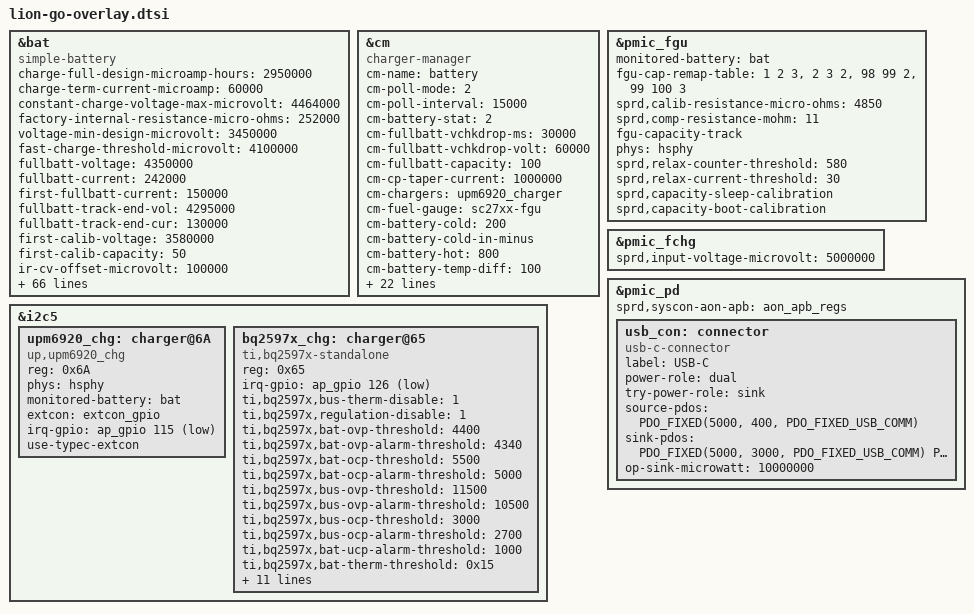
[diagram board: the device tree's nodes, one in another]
// SPDX-License-Identifier: GPL-2.0-only
/*
 * Unisoc Qogirl6 platform DTS file
 *
 * Copyright (C) 2020, Unisoc Inc.
 */

#include <dt-bindings/usb/pd.h>

&bat {
	compatible = "simple-battery";
	status = "okay";
	charge-full-design-microamp-hours = <2950000>;
	charge-term-current-microamp = <60000>;
	constant-charge-voltage-max-microvolt = <4464000>;
	factory-internal-resistance-micro-ohms = <252000>;
	voltage-min-design-microvolt = <3450000>;

	fast-charge-threshold-microvolt = <4100000>;
	fullbatt-voltage = <4350000>;
	fullbatt-current = <242000>;
	first-fullbatt-current = <150000>;
	fullbatt-track-end-vol = <4295000>;
	fullbatt-track-end-cur = <130000>;
	first-calib-voltage = <3580000>;
	first-calib-capacity = <50>;

	ir-cv-offset-microvolt = <100000>;
	ir-rc-micro-ohms = <20000>;
	ir-us-upper-limit-microvolt = <4500000>;

	ocv-capacity-celsius = <20>;
	ocv-capacity-table-0 = <4313000 100>, <4254000 95>, <4201000 90>,
				<4151000 85>, <4102000 80>, <4060000 75>,
				<4006000 70>, <3973000 65>, <3930000 60>,
				<3882000 55>, <3851000 50>, <3829000 45>,
				<3810000 40>, <3795000 35>, <3781000 30>,
				<3765000 25>, <3746000 20>, <3722000 15>,
				<3694000 10>, <3682000 5>, <3400000 0>;
	voltage-temp-table = <1110270 800>, <999440 850>, <890430 900>,
				<785590 950>, <687630 1000>, <598220 1050>,
				<517680 1100>, <446100 1150>, <383390 1200>,
				<328950 1250>, <281840 1300>, <241480 1350>,
				<207030 1400>, <177580 1450>, <152490 1500>,
				<131160 1550>, <113000 1600>, <97790 1650>;
	capacity-temp-table = <45 100>, <25 100>, <10 100>, <0 95>, <(-10) 90>;
	resistance-temp-table = <45 53>, <25 100>, <10 395>, <0 567>, <(-10) 793>;
	charge-sdp-current-microamp = <500000 500000>;
	charge-dcp-current-microamp = <3200000 3200000>;
	charge-cdp-current-microamp = <1500000 1500000>;
	charge-unknown-current-microamp = <1000000 1000000>;
	charge-fchg-current-microamp = <3000000 2000000>;
	charge-flash-current-microamp = <5000000 2700000>;

	cap-calib-energy-density-ocv-table = <3350000 3800000>, <4150000 4350000>;
	cap-track-energy-density-ocv-table = <3400000 3722000>;

	dcp-jeita-temp-table = <800 830 0 4200000>,<1000 1003 1000000 4200000>, <1100 1103 3200000 4500000>,
		<1150 1153 3200000 4500000>,<1450 1453 3200000 4530000>, <1600 1570 3200000 4200000>;
	sdp-jeita-temp-table = <800 803 0 4200000>,<1000 1003 500000 4200000>, <1100 1103 500000 4500000>,
		<1150 1153 500000 4500000>,<1450 1453 500000 4530000>, <1600 1570 500000 4200000>;
	cdp-jeita-temp-table = <800 830 0 4200000>,<1000 1030 1000000 4200000>, <1100 1103 1500000 4500000>,
		<1150 1153 1500000 4500000>,<1450 1453 1500000 4530000>, <1600 1570 1500000 4200000>;
	unknown-jeita-temp-table =<800 830 0 4200000>, <1000 1003 1000000 4200000>, <1100 1103 2000000 4500000>,
		<1150 1153 3000000 4500000>,<1450 1453 2000000 4530000>, <1600 1570 2000000 4200000>;
	fchg-jeita-temp-table =<800 830 0 4200000>,  <1000 1003 1000000 4200000>, <1100 1103 3000000 4500000>,
		<1150 1153 3480000 4500000>,<1450 1453 3480000 4530000>, <1600 1570 3480000 4200000>;
	flash-jeita-temp-table = <1000 1030 0 4200000>, <1150 1180 1000000 4500000>,
		<1450 1420 5000000 4530000>, <1600 1570 1000000 4340000>;
};

&cm {
	compatible = "charger-manager";
	status = "okay";
	cm-name = "battery";
	cm-poll-mode = <2>;
	cm-poll-interval = <15000>;
	cm-battery-stat = <2>;

	cm-fullbatt-vchkdrop-ms = <30000>;
	cm-fullbatt-vchkdrop-volt = <60000>;
	cm-fullbatt-capacity = <100>;
	/*Charge pump target charge current*/
	cm-cp-taper-current = <1000000>;

	cm-chargers = "upm6920_charger";
	//cm-chargers = "sgm41513_charger", "upm6920_charger";
	//cm-charge-pumps = "bq2597x-standalone";
	cm-fuel-gauge = "sc27xx-fgu";

	/* in deci centigrade */
	cm-battery-cold = <200>;
	cm-battery-cold-in-minus;
	cm-battery-hot = <800>;
	cm-battery-temp-diff = <100>;

	/* Allow charging for 6hr */
	cm-charging-max = <21600000>;
	/* recovery charging after stop charging 45min */
	cm-discharging-max = <2700000>;

	/* the interval to feed charger watchdog */
	cm-wdt-interval = <60>;

	/* drop voltage in microVolts to allow shutdown */
	cm-shutdown-voltage = <3100000>;

	/* when 99% of the time is exceeded, it will be forced to 100% */
	cm-tickle-time-out = <1500>;

	/* how much time to allow capacity change */
	cm-one-cap-time = <30>;

	cm-thermal-zone = "board-thmzone";

	/* when the safe charging voltage is exceeded, stop charging */
	cm-charge-voltage-max = <6500000>;
	cm-fast-charge-voltage-max = <10500000>;
	cm-flash-charge-voltage-max = <12000000>;
	/* drop voltage in microVolts to restart charging */
	cm-charge-voltage-drop = <700000>;
	cm-fast-charge-voltage-drop = <700000>;
	cm-flash-charge-voltage-drop = <1000000>;

	/* sprd_fchg parameter */
	sprd,support-fchg;
	sprd,support-pd-pps;
	sprd,pd-fixed-max-microwatt = <18000000>;

	monitored-battery = <&bat>;
	cm-capacity-track;
	cm-keep-awake;

	phys = <&hsphy>;
	pd-extcon-enable;
	extcon = <&pmic_typec>, <&pmic_pd>;
};

&i2c5 {
	#address-cells = <1>;
	#size-cells = <0>;

	status = "okay";

	upm6920_chg: charger@6A {
		compatible = "up,upm6920_chg";
		reg = <0x6A>;
		phys = <&hsphy>;
		monitored-battery = <&bat>;
		extcon = <&extcon_gpio>;
		irq-gpio = <&ap_gpio 115 GPIO_ACTIVE_LOW>;
		use-typec-extcon;
	};

	/*sgm41513_chg: charger@0B {
                compatible = "sgm,sgm41513_chg";
                reg = <0x0B>;
		phys = <&hsphy>;
                monitored-battery = <&bat>;
		extcon = <&extcon_gpio>;
                irq-gpio = <&ap_gpio 115 GPIO_ACTIVE_LOW>;
		use-typec-extcon;
        };*/

	/*bq2560x_chg: charger@6b {
		compatible = "ti,bq2560x_chg";
		reg = <0x6b>;
		monitored-battery = <&bat>;
		irq-gpio = <&ap_gpio 115 GPIO_ACTIVE_LOW>;
		vddvbus:otg-vbus {
			regulator-name = "vddvbus";
		};
	};*/

	bq2597x_chg: charger@65 {
		compatible = "ti,bq2597x-standalone";
		reg = <0x65>;
		irq-gpio = <&ap_gpio 126 GPIO_ACTIVE_LOW>;

		ti,bq2597x,bus-therm-disable = <1>;
		ti,bq2597x,regulation-disable = <1>;

		ti,bq2597x,bat-ovp-threshold = <4400>;
		ti,bq2597x,bat-ovp-alarm-threshold = <4340>;
		ti,bq2597x,bat-ocp-threshold = <5500>;
		ti,bq2597x,bat-ocp-alarm-threshold = <5000>;
		ti,bq2597x,bus-ovp-threshold = <11500>;
		ti,bq2597x,bus-ovp-alarm-threshold = <10500>;
		ti,bq2597x,bus-ocp-threshold = <3000>;
		ti,bq2597x,bus-ocp-alarm-threshold = <2700>;
		ti,bq2597x,bat-ucp-alarm-threshold = <1000>;
		ti,bq2597x,bat-therm-threshold = <0x15>;
		ti,bq2597x,bus-therm-threshold = <0x15>;
		ti,bq2597x,die-therm-threshold = <0xc8>;
		ti,bq2597x,ac-ovp-threshold = <13>;
		ti,bq2597x,sense-resistor-mohm = <5>;
		ti,bq2597x,adc-sample-bits = <13>;
		ti,bq2597x,ibat-regulation-threshold = <300>;
		ti,bq2597x,vbat-regulation-threshold = <100>;
		ti,bq2597x,vdrop-threshold = <400>;
		ti,bq2597x,vdrop-deglitch = <5000>;
		ti,bq2597x,ss-timeout = <100000>;
		ti,bq2597x,watchdog-timer = <30000>;
	};
};

&pmic_fgu {
	monitored-battery = <&bat>;
	fgu-cap-remap-table = <1 2 3>, <2 3 2>, <98 99 2>, <99 100 3>;
	sprd,calib-resistance-micro-ohms = <4850>;
	sprd,comp-resistance-mohm = <11>;

	fgu-capacity-track;
	phys = <&hsphy>;

	sprd,relax-counter-threshold = <580>;
	sprd,relax-current-threshold = <30>;
	sprd,capacity-sleep-calibration;

	sprd,capacity-boot-calibration;
};

&pmic_fchg {
	status = "okay";
	sprd,input-voltage-microvolt = <5000000>;
};

&pmic_pd {
	status = "okay";
	sprd,syscon-aon-apb = <&aon_apb_regs>;
	usb_con: connector {
		compatible = "usb-c-connector";
		label = "USB-C";
		power-role = "dual";
		try-power-role = "sink";
		source-pdos = <PDO_FIXED(5000, 400, PDO_FIXED_USB_COMM)>;
		sink-pdos = <PDO_FIXED(5000, 3000, PDO_FIXED_USB_COMM)
				PDO_PPS_APDO(3300, 11000, 3000)>;
		op-sink-microwatt = <10000000>;
	};
};
